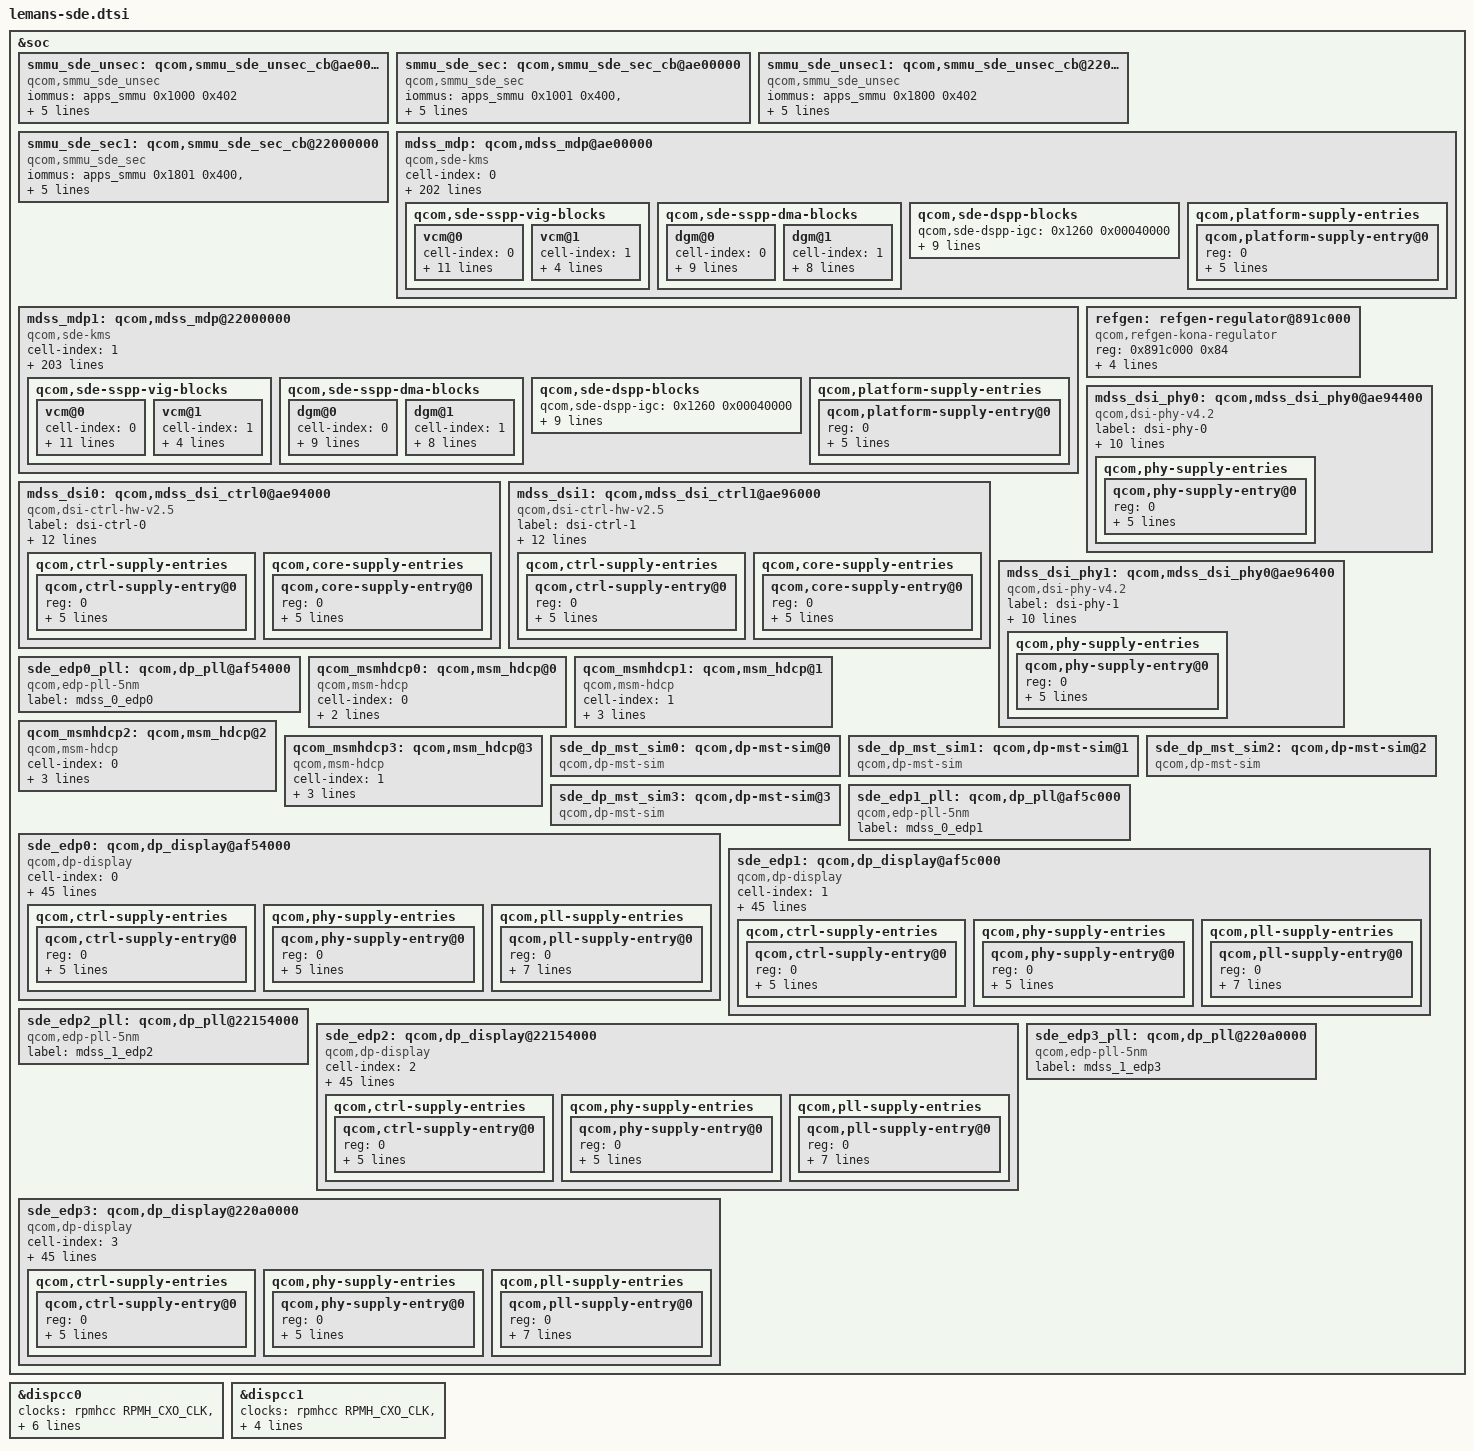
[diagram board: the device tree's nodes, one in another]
#include <dt-bindings/interrupt-controller/irq.h>
#include <dt-bindings/interconnect/qcom,lemans.h>
#include <dt-bindings/regulator/qcom,rpmh-regulator-levels.h>
#include <dt-bindings/clock/qcom,rpmh.h>
#include <dt-bindings/clock/qcom,gcc-lemans.h>
#include <dt-bindings/clock/qcom,dispcc-lemans.h>

&soc {
	smmu_sde_unsec: qcom,smmu_sde_unsec_cb@ae00000 {
		compatible = "qcom,smmu_sde_unsec";
		iommus = <&apps_smmu 0x1000 0x402>;
		qcom,iommu-dma-addr-pool = <0x00020000 0xfffe0000>;
		qcom,iommu-faults = "non-fatal";
		qcom,iommu-earlymap;
		dma-coherent-hint-cached;
	};

	smmu_sde_sec: qcom,smmu_sde_sec_cb@ae00000 {
		compatible = "qcom,smmu_sde_sec";
		iommus = <&apps_smmu 0x1001 0x400>,
			<&apps_smmu 0x1401 0x400>;
		qcom,iommu-dma-addr-pool = <0x00020000 0xfffe0000>;
		qcom,iommu-faults = "non-fatal";
		qcom,iommu-vmid = <0xa>;
	};

	smmu_sde_unsec1: qcom,smmu_sde_unsec_cb@22000000 {
		compatible = "qcom,smmu_sde_unsec";
		iommus = <&apps_smmu 0x1800 0x402>;
		qcom,iommu-dma-addr-pool = <0x00020000 0xfffe0000>;
		qcom,iommu-faults = "non-fatal";
		qcom,iommu-earlymap;
		dma-coherent-hint-cached;
	};

	smmu_sde_sec1: qcom,smmu_sde_sec_cb@22000000 {
		compatible = "qcom,smmu_sde_sec";
		iommus = <&apps_smmu 0x1801 0x400>,
			<&apps_smmu 0x1c01 0x400>;
		qcom,iommu-dma-addr-pool = <0x00020000 0xfffe0000>;
		qcom,iommu-faults = "non-fatal";
		qcom,iommu-vmid = <0xa>;
	};

	mdss_mdp: qcom,mdss_mdp@ae00000 {
		compatible = "qcom,sde-kms";

		cell-index = <0>;

		reg = <0x0ae00000 0x84000>,
				<0x0aeb0000 0x2008>,
				<0x0aeac000 0x800>;
		reg-names = "mdp_phys",
				"vbif_phys",
				"regdma_phys";

		clocks = <&gcc GCC_DISP_HF_AXI_CLK>,
				<&dispcc0 DISP_CC_MDSS_AHB_CLK>,
				<&dispcc0 DISP_CC_MDSS_MDP_CLK>,
				<&dispcc0 DISP_CC_MDSS_VSYNC_CLK>,
				<&dispcc0 DISP_CC_MDSS_MDP_LUT_CLK>;
		clock-names = "gcc_bus", "iface_clk",
				"core_clk", "vsync_clk", "lut_clk";
		clock-rate = <0 0 300000000 19200000 300000000>;
		clock-max-rate = <0 0 460000000 19200000 460000000>;

		sde-vdd-supply = <&disp0_cc_mdss_core_gdsc>;
		mmcx-supply = <&VDD_MMCX_LEVEL>;

		/* interrupt config */
		interrupts = <0 92 IRQ_TYPE_LEVEL_HIGH>;
		interrupt-controller;
		#interrupt-cells = <1>;

		#address-cells = <1>;
		#size-cells = <0>;

		#power-domain-cells = <0>;

		/* hw blocks */
		qcom,sde-off = <0x1000>;
		qcom,sde-len = <0x494>;

		qcom,sde-ctl-off = <0x16000 0x17000 0x18000
				0x19000 0x1a000 0x1b000>;
		qcom,sde-ctl-size = <0x204>;
		qcom,sde-ctl-display-pref = "primary", "none", "none",
				"none", "none", "none";

		qcom,sde-mixer-off = <0x45000 0x46000 0x47000
				0x48000 0x49000 0x4a000
				0x0f0f 0x0f0f>;
		qcom,sde-mixer-size = <0x400>;
		qcom,sde-mixer-display-pref = "primary", "none", "none",
				"none", "none", "none", "none", "none";

		qcom,sde-mixer-dcwb-pref = "none", "none", "none", "none",
				"none", "none", "dcwb", "dcwb";

		qcom,sde-dspp-top-off = <0x1300>;
		qcom,sde-dspp-top-size = <0x80>;
		qcom,sde-dspp-off = <0x55000 0x57000 0x59000 0x5b000>;
		qcom,sde-dspp-size = <0x1800>;

		qcom,sde-dspp-rc-version = <0x00010000>;
		qcom,sde-dspp-rc-off = <0x15800 0x14c00>;
		qcom,sde-dspp-rc-size = <0x100>;
		qcom,sde-dspp-rc-mem-size = <2720>;

		qcom,sde-dest-scaler-top-off = <0x00061000>;
		qcom,sde-dest-scaler-top-size = <0x1c>;
		qcom,sde-dest-scaler-off = <0x800 0x1000>;
		qcom,sde-dest-scaler-size = <0x800>;

		qcom,sde-wb-off = <0x66000>;
		qcom,sde-wb-size = <0x2c8>;
		qcom,sde-wb-xin-id = <6>;
		qcom,sde-wb-id = <2>;
		qcom,sde-wb-clk-ctrl = <0x2bc 16>;
		qcom,sde-wb-clk-status = <0x3bc 20>;

		qcom,sde-intf-off = <0x35000 0x36000 0x37000 0x38000
				0x39000 0x3a000 0x3b000 0x3c000 0x3d000>;
		qcom,sde-intf-size = <0x2c4>;
		qcom,sde-intf-type = "dp", "dsi", "dsi", "dp",
				"dp", "dp", "dp", "dp", "dp";
		qcom,sde-intf-tear-irq-off = <0 0x36800 0x37800 0
				0 0 0 0 0>;

		qcom,sde-pp-off = <0x6a000 0x6b000 0x6c000 0x6d000
				0x6e000 0x6f000 0x66800 0x66c00>;
		qcom,sde-pp-slave = <0x0 0x0 0x0 0x0 0x0 0x0 0x0 0x0>;
		qcom,sde-pp-size = <0xd4>;
		qcom,sde-pp-merge-3d-id = <0x0 0x0 0x1 0x1 0x2 0x2 0x3 0x3>;

		qcom,sde-merge-3d-off = <0x4f000 0x50000 0x51000 0x66f00>;
		qcom,sde-merge-3d-size = <0x10>;
		qcom,sde-pp-cwb = <0x0 0x0 0x0 0x0 0x0 0x0 0x1 0x1>;

		qcom,sde-cdm-off = <0x7a200>;
		qcom,sde-cdm-size = <0x224>;

		qcom,sde-dsc-off = <0x81000 0x81000 0x82000 0x82000>;
		qcom,sde-dsc-size = <0x10>;
		qcom,sde-dsc-pair-mask = <2 1 4 3>;
		qcom,sde-dsc-hw-rev = "dsc_1_2";
		qcom,sde-dsc-enc = <0x100 0x200 0x100 0x200>;
		qcom,sde-dsc-enc-size = <0x100>;
		qcom,sde-dsc-ctl = <0xF00 0xF80 0xF00 0xF80>;
		qcom,sde-dsc-ctl-size = <0x10>;
		qcom,sde-dsc-native422-supp = <0 0 1 1>;
		qcom,sde-dsc-linewidth = <2560>;

		qcom,sde-roi-misr-off = <0x72000 0x73000 0x74000
				0x75000 0x76000 0x77000>;
		qcom,sde-roi-misr-size = <0x180>;
		qcom,sde-roi-misr-bypass-off = <0xA00>;
		qcom,sde-roi-misr-bypass-size = <0xC0>;

		qcom,sde-dither-off = <0xe0 0xe0 0xe0
				0xe0 0xe0 0xe0 0xe0 0xe0>;
		qcom,sde-cwb-dither = <0x0 0x0 0x0 0x0 0x0 0x0 0x1 0x1>;
		qcom,sde-dither-version = <0x00020000>;
		qcom,sde-dither-size = <0x20>;

		qcom,sde-sspp-type = "vig", "vig", "vig", "vig",
				"dma", "dma", "dma", "dma";

		qcom,sde-sspp-off = <0x5000 0x7000 0x9000 0xb000
				0x25000 0x27000 0x29000 0x2b000>;
		qcom,sde-sspp-src-size = <0x328>;

		qcom,sde-sspp-xin-id = <0 4 8 12
				1 5 9 13>;
		qcom,sde-sspp-excl-rect = <1 1 1 1
				1 1 1 1>;
		qcom,sde-sspp-smart-dma-priority = <5 6 7 8 1 2 3 4>;
		qcom,sde-smart-dma-rev = "smart_dma_v2p5";

		qcom,sde-mixer-pair-mask = <2 1 4 3 6 5 8 7>;

		qcom,sde-mixer-blend-op-off = <0x20 0x38 0x50 0x68 0x80 0x98
				0xb0 0xc8 0xe0 0xf8 0x110>;

		qcom,sde-max-per-pipe-bw-kbps = <4500000 4500000
				4500000 4500000
				4500000 4500000
				4500000 4500000>;

		qcom,sde-max-per-pipe-bw-high-kbps = <5200000 5200000
				5200000 5200000
				5200000 5200000
				5200000 5200000>;

		/* offsets are relative to "mdp_phys + qcom,sde-off */
		qcom,sde-sspp-clk-ctrl =
				<0x2ac 0>, <0x2b4 0>,
				<0x2bc 0>, <0x2c4 0>,
				<0x2ac 8>, <0x2b4 8>,
				<0x2bc 8>, <0x2c4 8>;
		qcom,sde-sspp-clk-status =
				<0x2b0 0>, <0x2b8 0>,
				<0x2c0 0>, <0x2c8 0>,
				<0x2b0 12>, <0x2b8 12>,
				<0x2c8 12>, <0x2c8 14>;
		qcom,sde-sspp-csc-off = <0x1a00>;
		qcom,sde-csc-type = "csc-10bit";
		qcom,sde-qseed-sw-lib-rev = "qseedv3lite";
		qcom,sde-qseed-scalar-version = <0x3000>;
		qcom,sde-sspp-qseed-off = <0xa00>;
		qcom,sde-mixer-linewidth = <2560>;
		qcom,sde-sspp-linewidth = <5120>;
		qcom,sde-wb-linewidth = <4096>;
		qcom,sde-wb-linewidth-linear = <5120>;
		qcom,sde-mixer-blendstages = <0xb>;
		qcom,sde-highest-bank-bit = <0x8 0x0>,
				<0x7 0x2>;
		qcom,sde-ubwc-version = <0x40000000>;
		qcom,sde-ubwc-swizzle = <0x4>;
		qcom,sde-ubwc-bw-calc-version = <0x1>;
		qcom,sde-ubwc-static = <0x1>;
		qcom,sde-macrotile-mode = <0x1>;
		qcom,sde-smart-panel-align-mode = <0xc>;
		qcom,sde-panic-per-pipe;
		qcom,sde-has-cdp;
		qcom,sde-has-src-split;
		qcom,sde-pipe-order-version = <0x1>;
		qcom,sde-has-dim-layer;
		qcom,sde-has-idle-pc;

		qcom,sde-dspp-ltm-version = <0x00010001>;
		/* offsets are based off dspp 0 and dspp 1 */
		qcom,sde-dspp-ltm-off = <0x15300 0x14300>;

		qcom,sde-max-dest-scaler-input-linewidth = <2048>;
		qcom,sde-max-dest-scaler-output-linewidth = <2560>;
		qcom,sde-max-bw-low-kbps = <13600000>;
		qcom,sde-max-bw-high-kbps = <18200000>;
		qcom,sde-min-core-ib-kbps = <2500000>;
		qcom,sde-min-llcc-ib-kbps = <0>;
		qcom,sde-min-dram-ib-kbps = <800000>;
		qcom,sde-dram-channels = <2>;
		qcom,sde-num-nrt-paths = <0>;

		qcom,sde-dspp-demura-off = <0x15600 0x14800>;
		qcom,sde-dspp-demura-size = <0x200>;
		qcom,sde-dspp-demura-version = <0x00010000>;

		qcom,sde-lm-noise-off = <0x320>;
		qcom,sde-lm-noise-version = <0x00010000>;

		qcom,sde-uidle-off = <0x80000>;
		qcom,sde-uidle-size = <0x70>;

		qcom,sde-vbif-off = <0>;
		qcom,sde-vbif-size = <0x1040>;
		qcom,sde-vbif-id = <0>;
		qcom,sde-vbif-memtype-0 = <3 3 3 3 3 3 3 3>;
		qcom,sde-vbif-memtype-1 = <3 3 3 3 3 3>;

		qcom,sde-vbif-default-ot-wr-limit = <16>;
		qcom,sde-vbif-dynamic-ot-wr-limit = <62208000 2 124416000 6 497664000 16>;

		qcom,sde-vbif-qos-rt-remap = <3 3 4 4 5 5 6 6 3 3 4 4 5 5 6 6>;
		qcom,sde-vbif-qos-nrt-remap = <3 3 3 3 3 3 3 3 3 3 3 3 3 3 3 3>;
		qcom,sde-vbif-qos-cwb-remap = <3 3 4 4 5 5 6 6 3 3 4 4 5 5 6 6>;
		qcom,sde-vbif-qos-lutdma-remap = <3 3 3 3 4 4 4 6 3 3 3 3 4 4 4 6>;

		qcom,sde-qos-refresh-rates = <120 240>;
		qcom,sde-danger-lut = <0x3ffff 0x3ffff 0x0 0x0 0x0 0x3fffff 0x3fffff>,
				<0x3ffffff 0x3ffffff 0x0 0x0 0x0 0x3ffffff 0x3fffff>;

		qcom,sde-safe-lut = <0xFE00 0xFE00 0xFFFF 0x01 0x03FF 0xF800 0xF800>,
				<0xE000 0xE000 0xFFFF 0x01 0x03FF 0xE000 0xF800>;

		qcom,sde-creq-lut =
				<0x00112234 0x45566777 0x00112236 0x67777777
				    0x00112234 0x45566777 0x00112236 0x67777777
				    0x0        0x0         0x0        0x0
				    0x77776666 0x66666540 0x77776666 0x66666540
				    0x77776541 0x00000000 0x77776541 0x00000000
				    0x00123445 0x56677777 0x00123667 0x77777777
				    0x00123445 0x56677777 0x00123667 0x77777777>,
				<0x02344455 0x56667777 0x02366677 0x77777777
				    0x02344455 0x56667777 0x02366677 0x77777777
				    0x0        0x0        0x0        0x0
				    0x77776666 0x66666540 0x77776666 0x66666540
				    0x77776541 0x00000000 0x77776541 0x00000000
				    0x02344455 0x56667777 0x02366677 0x77777777
				    0x00123445 0x56677777 0x00123667 0x77777777>;

		qcom,sde-cdp-setting = <1 1>, <1 0>;

		qcom,sde-qos-cpu-mask = <0x3>;
		qcom,sde-qos-cpu-mask-performance = <0xf>;
		qcom,sde-qos-cpu-dma-latency = <300>;
		qcom,sde-qos-cpu-irq-latency = <300>;

		/* offsets are relative to "mdp_phys + qcom,sde-off */
		qcom,sde-reg-dma-off = <0 0x400>;
		qcom,sde-reg-dma-id = <0 1>;
		qcom,sde-reg-dma-version = <0x00020000>;
		qcom,sde-reg-dma-trigger-off = <0x119c>;
		qcom,sde-reg-dma-xin-id = <7>;
		qcom,sde-reg-dma-clk-ctrl = <0x2bc 20>;

		qcom,sde-secure-sid-mask = <0x4000821>;

		qcom,sde-reg-bus,vectors-KBps = <0 0>,
				<0 74000>,
				<0 148000>,
				<0 265000>;

		/* data and reg bus scale settings */
		interconnects = <&mmss_noc MASTER_MDP0 &gem_noc SLAVE_LLCC>,
				<&mmss_noc MASTER_MDP1 &gem_noc SLAVE_LLCC>,
				<&mc_virt MASTER_LLCC &mc_virt SLAVE_EBI1>,
				<&gem_noc MASTER_APPSS_PROC &config_noc SLAVE_DISPLAY_CFG>;
		interconnect-names = "qcom,sde-data-bus0", "qcom,sde-data-bus1",
				"qcom,sde-ebi-bus", "qcom,sde-reg-bus";

		qcom,sde-ib-bw-vote = <2500000 0 800000>;

		qcom,sde-sspp-vig-blocks {
			vcm@0 {
				cell-index = <0>;
				qcom,sde-vig-top-off = <0xa00>;
				qcom,sde-vig-csc-off = <0x1a00>;
				qcom,sde-vig-qseed-off = <0xa00>;
				qcom,sde-vig-qseed-size = <0xe0>;
				qcom,sde-vig-gamut = <0x1d00 0x00060001>;
				qcom,sde-vig-igc = <0x1d00 0x00060000>;
				qcom,sde-vig-inverse-pma;
				qcom,sde-fp16-igc = <0x200 0x00010000>;
				qcom,sde-fp16-unmult = <0x200 0x00010000>;
				qcom,sde-fp16-gc = <0x200 0x00010000>;
				qcom,sde-fp16-csc = <0x200 0x00010000>;
			};

			vcm@1 {
				cell-index = <1>;
				qcom,sde-fp16-igc = <0x280 0x00010000>;
				qcom,sde-fp16-unmult = <0x280 0x00010000>;
				qcom,sde-fp16-gc = <0x280 0x00010000>;
				qcom,sde-fp16-csc = <0x280 0x00010000>;
			};
		};

		qcom,sde-sspp-dma-blocks {
			dgm@0 {
				cell-index = <0>;
				qcom,sde-dma-top-off = <0x800>;
				qcom,sde-dma-igc = <0xa00 0x00050000>;
				qcom,sde-dma-gc = <0xc00 0x00050000>;
				qcom,sde-dma-inverse-pma;
				qcom,sde-dma-csc-off = <0x800>;
				qcom,sde-fp16-igc = <0x200 0x00010000>;
				qcom,sde-fp16-unmult = <0x200 0x00010000>;
				qcom,sde-fp16-gc = <0x200 0x00010000>;
				qcom,sde-fp16-csc = <0x200 0x00010000>;
			};

			dgm@1 {
				cell-index = <1>;
				qcom,sde-dma-igc = <0x1a00 0x00050000>;
				qcom,sde-dma-gc = <0xc00 0x00050000>;
				qcom,sde-dma-inverse-pma;
				qcom,sde-dma-csc-off = <0x1800>;
				qcom,sde-fp16-igc = <0x200 0x00010000>;
				qcom,sde-fp16-unmult = <0x200 0x00010000>;
				qcom,sde-fp16-gc = <0x200 0x00010000>;
				qcom,sde-fp16-csc = <0x200 0x00010000>;
			};
		};

		qcom,sde-dspp-blocks {
			qcom,sde-dspp-igc = <0x1260 0x00040000>;
			qcom,sde-dspp-hsic = <0x800 0x00010007>;
			qcom,sde-dspp-memcolor = <0x880 0x00010007>;
			qcom,sde-dspp-hist = <0x800 0x00010007>;
			qcom,sde-dspp-sixzone= <0x900 0x00010007>;
			qcom,sde-dspp-vlut = <0xa00 0x00010008>;
			qcom,sde-dspp-gamut = <0x1000 0x00040003>;
			qcom,sde-dspp-pcc = <0x1700 0x00040000>;
			qcom,sde-dspp-gc = <0x17c0 0x00010008>;
			qcom,sde-dspp-dither = <0x82c 0x00010007>;
		};

		qcom,platform-supply-entries {
			#address-cells = <1>;
			#size-cells = <0>;

			qcom,platform-supply-entry@0 {
				reg = <0>;
				qcom,supply-name = "mmcx";
				qcom,supply-min-voltage = <0>;
				qcom,supply-max-voltage = <0>;
				qcom,supply-enable-load = <0>;
				qcom,supply-disable-load = <0>;
			};
		};
	};

	mdss_mdp1: qcom,mdss_mdp@22000000 {
		compatible = "qcom,sde-kms";

		cell-index = <1>;

		reg = <0x22000000 0x84000>,
				<0x220b0000 0x2008>,
				<0x220ac000 0x800>;
		reg-names = "mdp_phys",
				"vbif_phys",
				"regdma_phys";

		clocks = <&gcc GCC_DISP1_HF_AXI_CLK>,
				<&dispcc1 DISP_CC_MDSS_AHB_CLK>,
				<&dispcc1 DISP_CC_MDSS_MDP_CLK>,
				<&dispcc1 DISP_CC_MDSS_VSYNC_CLK>,
				<&dispcc1 DISP_CC_MDSS_MDP_LUT_CLK>;
		clock-names = "gcc_bus", "iface_clk",
				"core_clk", "vsync_clk", "lut_clk";
		clock-rate = <0 0 300000000 19200000 300000000>;
		clock-max-rate = <0 0 460000000 19200000 460000000>;

		sde-vdd-supply = <&disp1_cc_mdss_core_gdsc>;
		mmcx-supply = <&VDD_MMCX_LEVEL>;

		/* interrupt config */
		interrupts = <0 865 IRQ_TYPE_LEVEL_HIGH>;
		interrupt-controller;
		#interrupt-cells = <1>;

		#address-cells = <1>;
		#size-cells = <0>;

		#power-domain-cells = <0>;

		/* hw blocks */
		qcom,sde-off = <0x1000>;
		qcom,sde-len = <0x494>;

		qcom,sde-ctl-off = <0x16000 0x17000 0x18000
				0x19000 0x1a000 0x1b000>;
		qcom,sde-ctl-size = <0x204>;
		qcom,sde-ctl-display-pref = "primary", "none", "none",
				"none", "none", "none";

		qcom,sde-mixer-off = <0x45000 0x46000 0x47000
				0x48000 0x49000 0x4a000
				0x0f0f 0x0f0f>;
		qcom,sde-mixer-size = <0x400>;
		qcom,sde-mixer-display-pref = "primary", "none", "none",
				"none", "none", "none", "none", "none";

		qcom,sde-mixer-dcwb-pref = "none", "none", "none", "none",
				"none", "none", "dcwb", "dcwb";

		qcom,sde-dspp-top-off = <0x1300>;
		qcom,sde-dspp-top-size = <0x80>;
		qcom,sde-dspp-off = <0x55000 0x57000 0x59000 0x5b000>;
		qcom,sde-dspp-size = <0x1800>;

		qcom,sde-dspp-rc-version = <0x00010000>;
		qcom,sde-dspp-rc-off = <0x15800 0x14c00>;
		qcom,sde-dspp-rc-size = <0x100>;
		qcom,sde-dspp-rc-mem-size = <2720>;

		qcom,sde-dest-scaler-top-off = <0x00061000>;
		qcom,sde-dest-scaler-top-size = <0x1c>;
		qcom,sde-dest-scaler-off = <0x800 0x1000>;
		qcom,sde-dest-scaler-size = <0x800>;

		qcom,sde-wb-off = <0x66000>;
		qcom,sde-wb-size = <0x2c8>;
		qcom,sde-wb-xin-id = <6>;
		qcom,sde-wb-id = <2>;
		qcom,sde-wb-clk-ctrl = <0x2bc 16>;
		qcom,sde-wb-clk-status = <0x3bc 20>;

		qcom,sde-intf-off = <0x35000 0x36000 0x37000 0x38000
				0x39000 0x3a000 0x3b000 0x3c000 0x3d000>;
		qcom,sde-intf-size = <0x2c4>;
		qcom,sde-intf-type = "dp", "dsi", "dsi", "dp",
				"dp", "dp", "dp", "dp", "dp";
		qcom,sde-intf-tear-irq-off = <0 0x36800 0x37800 0
				0 0 0 0 0>;

		qcom,sde-pp-off = <0x6a000 0x6b000 0x6c000 0x6d000
				0x6e000 0x6f000 0x66800 0x66c00>;
		qcom,sde-pp-slave = <0x0 0x0 0x0 0x0 0x0 0x0 0x0 0x0>;
		qcom,sde-pp-size = <0xd4>;
		qcom,sde-pp-merge-3d-id = <0x0 0x0 0x1 0x1 0x2 0x2 0x3 0x3>;

		qcom,sde-merge-3d-off = <0x4f000 0x50000 0x51000 0x66f00>;
		qcom,sde-merge-3d-size = <0x10>;
		qcom,sde-pp-cwb = <0x0 0x0 0x0 0x0 0x0 0x0 0x1 0x1>;

		qcom,sde-cdm-off = <0x7a200>;
		qcom,sde-cdm-size = <0x224>;

		qcom,sde-dsc-off = <0x81000 0x81000 0x82000 0x82000>;
		qcom,sde-dsc-size = <0x10>;
		qcom,sde-dsc-pair-mask = <2 1 4 3>;
		qcom,sde-dsc-hw-rev = "dsc_1_2";
		qcom,sde-dsc-enc = <0x100 0x200 0x100 0x200>;
		qcom,sde-dsc-enc-size = <0x100>;
		qcom,sde-dsc-ctl = <0xF00 0xF80 0xF00 0xF80>;
		qcom,sde-dsc-ctl-size = <0x10>;
		qcom,sde-dsc-native422-supp = <0 0 1 1>;
		qcom,sde-dsc-linewidth = <2560>;

		qcom,sde-roi-misr-off = <0x72000 0x73000 0x74000
				0x75000 0x76000 0x77000>;
		qcom,sde-roi-misr-size = <0x180>;
		qcom,sde-roi-misr-bypass-off = <0xA00>;
		qcom,sde-roi-misr-bypass-size = <0xC0>;

		qcom,sde-dither-off = <0xe0 0xe0 0xe0
				0xe0 0xe0 0xe0 0xe0 0xe0>;
		qcom,sde-cwb-dither = <0x0 0x0 0x0 0x0 0x0 0x0 0x1 0x1>;
		qcom,sde-dither-version = <0x00020000>;
		qcom,sde-dither-size = <0x20>;

		qcom,sde-sspp-type = "vig", "vig", "vig", "vig",
				"dma", "dma", "dma", "dma";

		qcom,sde-sspp-off = <0x5000 0x7000 0x9000 0xb000
				0x25000 0x27000 0x29000 0x2b000>;
		qcom,sde-sspp-src-size = <0x328>;

		qcom,sde-sspp-xin-id = <0 4 8 12
				1 5 9 13>;
		qcom,sde-sspp-excl-rect = <1 1 1 1
				1 1 1 1>;
		qcom,sde-sspp-smart-dma-priority = <5 6 7 8 1 2 3 4>;
		qcom,sde-smart-dma-rev = "smart_dma_v2p5";

		qcom,sde-mixer-pair-mask = <2 1 4 3 6 5 8 7>;

		qcom,sde-mixer-blend-op-off = <0x20 0x38 0x50 0x68 0x80 0x98
				0xb0 0xc8 0xe0 0xf8 0x110>;

		qcom,sde-max-per-pipe-bw-kbps = <4500000 4500000
				4500000 4500000
				4500000 4500000
				4500000 4500000>;

		qcom,sde-max-per-pipe-bw-high-kbps = <5200000 5200000
				5200000 5200000
				5200000 5200000
				5200000 5200000>;

		/* offsets are relative to "mdp_phys + qcom,sde-off */
		qcom,sde-sspp-clk-ctrl =
				<0x2ac 0>, <0x2b4 0>,
				<0x2bc 0>, <0x2c4 0>,
				<0x2ac 8>, <0x2b4 8>,
				<0x2bc 8>, <0x2c4 8>;
		qcom,sde-sspp-clk-status =
				<0x2b0 0>, <0x2b8 0>,
				<0x2c0 0>, <0x2c8 0>,
				<0x2b0 12>, <0x2b8 12>,
				<0x2c8 12>, <0x2c8 14>;
		qcom,sde-sspp-csc-off = <0x1a00>;
		qcom,sde-csc-type = "csc-10bit";
		qcom,sde-qseed-sw-lib-rev = "qseedv3lite";
		qcom,sde-qseed-scalar-version = <0x3000>;
		qcom,sde-sspp-qseed-off = <0xa00>;
		qcom,sde-mixer-linewidth = <2560>;
		qcom,sde-sspp-linewidth = <5120>;
		qcom,sde-wb-linewidth = <4096>;
		qcom,sde-wb-linewidth-linear = <5120>;
		qcom,sde-mixer-blendstages = <0xb>;
		qcom,sde-highest-bank-bit = <0x8 0x0>,
				<0x7 0x2>;
		qcom,sde-ubwc-version = <0x40000000>;
		qcom,sde-ubwc-swizzle = <0x4>;
		qcom,sde-ubwc-bw-calc-version = <0x1>;
		qcom,sde-ubwc-static = <0x1>;
		qcom,sde-macrotile-mode = <0x1>;
		qcom,sde-smart-panel-align-mode = <0xc>;
		qcom,sde-panic-per-pipe;
		qcom,sde-has-cdp;
		qcom,sde-has-src-split;
		qcom,sde-pipe-order-version = <0x1>;
		qcom,sde-has-dim-layer;
		qcom,sde-has-idle-pc;

		qcom,sde-dspp-ltm-version = <0x00010001>;
		/* offsets are based off dspp 0 and dspp 1 */
		qcom,sde-dspp-ltm-off = <0x15300 0x14300>;

		qcom,sde-max-dest-scaler-input-linewidth = <2048>;
		qcom,sde-max-dest-scaler-output-linewidth = <2560>;
		qcom,sde-max-bw-low-kbps = <13600000>;
		qcom,sde-max-bw-high-kbps = <18200000>;
		qcom,sde-min-core-ib-kbps = <2500000>;
		qcom,sde-min-llcc-ib-kbps = <0>;
		qcom,sde-min-dram-ib-kbps = <800000>;
		qcom,sde-dram-channels = <2>;
		qcom,sde-num-nrt-paths = <0>;

		qcom,sde-dspp-demura-off = <0x15600 0x14800>;
		qcom,sde-dspp-demura-size = <0x200>;
		qcom,sde-dspp-demura-version = <0x00010000>;

		qcom,sde-lm-noise-off = <0x320>;
		qcom,sde-lm-noise-version = <0x00010000>;

		qcom,sde-uidle-off = <0x80000>;
		qcom,sde-uidle-size = <0x70>;

		qcom,sde-vbif-off = <0>;
		qcom,sde-vbif-size = <0x1040>;
		qcom,sde-vbif-id = <0>;
		qcom,sde-vbif-memtype-0 = <3 3 3 3 3 3 3 3>;
		qcom,sde-vbif-memtype-1 = <3 3 3 3 3 3>;

		qcom,sde-vbif-default-ot-wr-limit = <16>;
		qcom,sde-vbif-dynamic-ot-wr-limit = <62208000 2 124416000 6 497664000 16>;

		qcom,sde-vbif-qos-rt-remap = <3 3 4 4 5 5 6 6 3 3 4 4 5 5 6 6>;
		qcom,sde-vbif-qos-nrt-remap = <3 3 3 3 3 3 3 3 3 3 3 3 3 3 3 3>;
		qcom,sde-vbif-qos-cwb-remap = <3 3 4 4 5 5 6 6 3 3 4 4 5 5 6 6>;
		qcom,sde-vbif-qos-lutdma-remap = <3 3 3 3 4 4 4 6 3 3 3 3 4 4 4 6>;

		qcom,sde-qos-refresh-rates = <120 240>;
		qcom,sde-danger-lut = <0x3ffff 0x3ffff 0x0 0x0 0x0 0x3fffff 0x3fffff>,
				<0x3ffffff 0x3ffffff 0x0 0x0 0x0 0x3ffffff 0x3fffff>;

		qcom,sde-safe-lut = <0xFE00 0xFE00 0xFFFF 0x01 0x03FF 0xF800 0xF800>,
				<0xE000 0xE000 0xFFFF 0x01 0x03FF 0xE000 0xF800>;

		qcom,sde-creq-lut =
				<0x00112234 0x45566777 0x00112236 0x67777777
				    0x00112234 0x45566777 0x00112236 0x67777777
				    0x0        0x0         0x0        0x0
				    0x77776666 0x66666540 0x77776666 0x66666540
				    0x77776541 0x00000000 0x77776541 0x00000000
				    0x00123445 0x56677777 0x00123667 0x77777777
				    0x00123445 0x56677777 0x00123667 0x77777777>,
				<0x02344455 0x56667777 0x02366677 0x77777777
				    0x02344455 0x56667777 0x02366677 0x77777777
				    0x0        0x0        0x0        0x0
				    0x77776666 0x66666540 0x77776666 0x66666540
				    0x77776541 0x00000000 0x77776541 0x00000000
				    0x02344455 0x56667777 0x02366677 0x77777777
				    0x00123445 0x56677777 0x00123667 0x77777777>;

		qcom,sde-cdp-setting = <1 1>, <1 0>;

		qcom,sde-qos-cpu-mask = <0x3>;
		qcom,sde-qos-cpu-mask-performance = <0xf>;
		qcom,sde-qos-cpu-dma-latency = <300>;
		qcom,sde-qos-cpu-irq-latency = <300>;

		/* offsets are relative to "mdp_phys + qcom,sde-off */
		qcom,sde-reg-dma-off = <0 0x400>;
		qcom,sde-reg-dma-id = <0 1>;
		qcom,sde-reg-dma-version = <0x00020000>;
		qcom,sde-reg-dma-trigger-off = <0x119c>;
		qcom,sde-reg-dma-xin-id = <7>;
		qcom,sde-reg-dma-clk-ctrl = <0x2bc 20>;

		qcom,sde-secure-sid-mask = <0x4000821>;

		qcom,sde-reg-bus,vectors-KBps = <0 0>,
				<0 74000>,
				<0 148000>,
				<0 265000>;

		/* data and reg bus scale settings */
		interconnects = <&mmss_noc MASTER_MDP_CORE1_0 &gem_noc SLAVE_LLCC>,
				<&mmss_noc MASTER_MDP_CORE1_1 &gem_noc SLAVE_LLCC>,
				<&mc_virt MASTER_LLCC &mc_virt SLAVE_EBI1>,
				<&gem_noc MASTER_APPSS_PROC &config_noc SLAVE_DISPLAY1_CFG>;
		interconnect-names = "qcom,sde-data-bus0", "qcom,sde-data-bus1",
				"qcom,sde-ebi-bus", "qcom,sde-reg-bus";

		qcom,sde-ib-bw-vote = <2500000 0 800000>;

		qcom,sde-sspp-vig-blocks {
			vcm@0 {
				cell-index = <0>;
				qcom,sde-vig-top-off = <0xa00>;
				qcom,sde-vig-csc-off = <0x1a00>;
				qcom,sde-vig-qseed-off = <0xa00>;
				qcom,sde-vig-qseed-size = <0xe0>;
				qcom,sde-vig-gamut = <0x1d00 0x00060001>;
				qcom,sde-vig-igc = <0x1d00 0x00060000>;
				qcom,sde-vig-inverse-pma;
				qcom,sde-fp16-igc = <0x200 0x00010000>;
				qcom,sde-fp16-unmult = <0x200 0x00010000>;
				qcom,sde-fp16-gc = <0x200 0x00010000>;
				qcom,sde-fp16-csc = <0x200 0x00010000>;
			};

			vcm@1 {
				cell-index = <1>;
				qcom,sde-fp16-igc = <0x280 0x00010000>;
				qcom,sde-fp16-unmult = <0x280 0x00010000>;
				qcom,sde-fp16-gc = <0x280 0x00010000>;
				qcom,sde-fp16-csc = <0x280 0x00010000>;
			};
		};

		qcom,sde-sspp-dma-blocks {
			dgm@0 {
				cell-index = <0>;
				qcom,sde-dma-top-off = <0x800>;
				qcom,sde-dma-igc = <0xa00 0x00050000>;
				qcom,sde-dma-gc = <0xc00 0x00050000>;
				qcom,sde-dma-inverse-pma;
				qcom,sde-dma-csc-off = <0x800>;
				qcom,sde-fp16-igc = <0x200 0x00010000>;
				qcom,sde-fp16-unmult = <0x200 0x00010000>;
				qcom,sde-fp16-gc = <0x200 0x00010000>;
				qcom,sde-fp16-csc = <0x200 0x00010000>;
			};

			dgm@1 {
				cell-index = <1>;
				qcom,sde-dma-igc = <0x1a00 0x00050000>;
				qcom,sde-dma-gc = <0xc00 0x00050000>;
				qcom,sde-dma-inverse-pma;
				qcom,sde-dma-csc-off = <0x1800>;
				qcom,sde-fp16-igc = <0x200 0x00010000>;
				qcom,sde-fp16-unmult = <0x200 0x00010000>;
				qcom,sde-fp16-gc = <0x200 0x00010000>;
				qcom,sde-fp16-csc = <0x200 0x00010000>;
			};
		};

		qcom,sde-dspp-blocks {
			qcom,sde-dspp-igc = <0x1260 0x00040000>;
			qcom,sde-dspp-hsic = <0x800 0x00010007>;
			qcom,sde-dspp-memcolor = <0x880 0x00010007>;
			qcom,sde-dspp-hist = <0x800 0x00010007>;
			qcom,sde-dspp-sixzone= <0x900 0x00010007>;
			qcom,sde-dspp-vlut = <0xa00 0x00010008>;
			qcom,sde-dspp-gamut = <0x1000 0x00040003>;
			qcom,sde-dspp-pcc = <0x1700 0x00040000>;
			qcom,sde-dspp-gc = <0x17c0 0x00010008>;
			qcom,sde-dspp-dither = <0x82c 0x00010007>;
		};

		qcom,platform-supply-entries {
			#address-cells = <1>;
			#size-cells = <0>;

			qcom,platform-supply-entry@0 {
				reg = <0>;
				qcom,supply-name = "mmcx";
				qcom,supply-min-voltage = <0>;
				qcom,supply-max-voltage = <0>;
				qcom,supply-enable-load = <0>;
				qcom,supply-disable-load = <0>;
			};
		};
	};

	refgen: refgen-regulator@891c000 {
		compatible = "qcom,refgen-kona-regulator";
		reg = <0x891c000 0x84>;
		regulator-name = "refgen";
		proxy-supply = <&refgen>;
		qcom,proxy-consumer-enable;
		regulator-enable-ramp-delay = <5>;
	};

	mdss_dsi0: qcom,mdss_dsi_ctrl0@ae94000 {
		compatible = "qcom,dsi-ctrl-hw-v2.5";
		label = "dsi-ctrl-0";
		cell-index = <0>;
		reg = <0xae94000 0x400>,
				<0xaf0f000 0x4>,
				<0xae36000 0x300>;
		reg-names = "dsi_ctrl", "disp_cc_base", "mdp_intf_base";
		interrupt-parent = <&mdss_mdp>;
		interrupts = <4 0>;
		clocks = <&dispcc0 DISP_CC_MDSS_BYTE0_CLK>,
				<&dispcc0 DISP_CC_MDSS_BYTE0_CLK_SRC>,
				<&dispcc0 DISP_CC_MDSS_BYTE0_INTF_CLK>,
				<&dispcc0 DISP_CC_MDSS_PCLK0_CLK>,
				<&dispcc0 DISP_CC_MDSS_PCLK0_CLK_SRC>,
				<&dispcc0 DISP_CC_MDSS_ESC0_CLK>,
				<&rpmhcc RPMH_CXO_CLK>;
		clock-names = "byte_clk", "byte_clk_rcg", "byte_intf_clk",
				"pixel_clk", "pixel_clk_rcg",
				"esc_clk", "xo";

		qcom,ctrl-supply-entries {
			#address-cells = <1>;
			#size-cells = <0>;

			qcom,ctrl-supply-entry@0 {
				reg = <0>;
				qcom,supply-name = "vdda-1p2";
				qcom,supply-min-voltage = <1200000>;
				qcom,supply-max-voltage = <1200000>;
				qcom,supply-enable-load = <30100>;
				qcom,supply-disable-load = <0>;
			};
		};

		qcom,core-supply-entries {
			#address-cells = <1>;
			#size-cells = <0>;
			qcom,core-supply-entry@0 {
				reg = <0>;
				qcom,supply-name = "refgen";
				qcom,supply-min-voltage = <0>;
				qcom,supply-max-voltage = <0>;
				qcom,supply-enable-load = <0>;
				qcom,supply-disable-load = <0>;
			};
		};
	};

	mdss_dsi1: qcom,mdss_dsi_ctrl1@ae96000 {
		compatible = "qcom,dsi-ctrl-hw-v2.5";
		label = "dsi-ctrl-1";
		cell-index = <1>;
		reg = <0xae96000 0x400>,
				<0xaf0f000 0x4>,
				<0xae37000 0x300>;
		reg-names = "dsi_ctrl", "disp_cc_base", "mdp_intf_base";
		interrupt-parent = <&mdss_mdp>;
		interrupts = <5 0>;
		clocks = <&dispcc0 DISP_CC_MDSS_BYTE1_CLK>,
				<&dispcc0 DISP_CC_MDSS_BYTE1_CLK_SRC>,
				<&dispcc0 DISP_CC_MDSS_BYTE1_INTF_CLK>,
				<&dispcc0 DISP_CC_MDSS_PCLK1_CLK>,
				<&dispcc0 DISP_CC_MDSS_PCLK1_CLK_SRC>,
				<&dispcc0 DISP_CC_MDSS_ESC1_CLK>,
				<&rpmhcc RPMH_CXO_CLK>;
		clock-names = "byte_clk", "byte_clk_rcg", "byte_intf_clk",
				"pixel_clk", "pixel_clk_rcg",
				"esc_clk", "xo";

		qcom,ctrl-supply-entries {
			#address-cells = <1>;
			#size-cells = <0>;

			qcom,ctrl-supply-entry@0 {
				reg = <0>;
				qcom,supply-name = "vdda-1p2";
				qcom,supply-min-voltage = <1200000>;
				qcom,supply-max-voltage = <1200000>;
				qcom,supply-enable-load = <30100>;
				qcom,supply-disable-load = <0>;
			};
		};

		qcom,core-supply-entries {
			#address-cells = <1>;
			#size-cells = <0>;
			qcom,core-supply-entry@0 {
				reg = <0>;
				qcom,supply-name = "refgen";
				qcom,supply-min-voltage = <0>;
				qcom,supply-max-voltage = <0>;
				qcom,supply-enable-load = <0>;
				qcom,supply-disable-load = <0>;
			};
		};
	};

	mdss_dsi_phy0: qcom,mdss_dsi_phy0@ae94400 {
		compatible = "qcom,dsi-phy-v4.2";
		label = "dsi-phy-0";
		cell-index = <0>;
		#clock-cells = <1>;

		reg = <0xae94400 0xa00>,
				<0xae94900 0x400>,
				<0xae94200 0xa0>;
		reg-names = "dsi_phy", "pll_base", "dyn_refresh_base";
		pll-label = "dsi_pll_5nm";

		qcom,platform-strength-ctrl = [55 03
				55 03
				55 03
				55 03
				55 00];
		qcom,platform-lane-config = [00 00 0a 0a
				00 00 0a 0a
				00 00 0a 0a
				00 00 0a 0a
				00 00 8a 8a];
		qcom,platform-regulator-settings = [1d 1d 1d 1d 1d];

		qcom,phy-supply-entries {
			#address-cells = <1>;
			#size-cells = <0>;
			qcom,phy-supply-entry@0 {
				reg = <0>;
				qcom,supply-name = "vdda-0p9";
				qcom,supply-min-voltage = <912000>;
				qcom,supply-max-voltage = <912000>;
				qcom,supply-enable-load = <115000>;
				qcom,supply-disable-load = <0>;
			};
		};
	};

	mdss_dsi_phy1: qcom,mdss_dsi_phy0@ae96400 {
		compatible = "qcom,dsi-phy-v4.2";
		label = "dsi-phy-1";
		cell-index = <1>;
		#clock-cells = <1>;
		reg = <0xae96400 0xa00>,
				<0xae96900 0x400>,
				<0xae96200 0xa0>;
		reg-names = "dsi_phy", "pll_base", "dyn_refresh_base";
		pll-label = "dsi_pll_5nm";

		qcom,platform-strength-ctrl = [55 03
				55 03
				55 03
				55 03
				55 00];
		qcom,platform-regulator-settings = [1d 1d 1d 1d 1d];
		qcom,platform-lane-config = [00 00 0a 0a
				00 00 0a 0a
				00 00 0a 0a
				00 00 0a 0a
				00 00 8a 8a];

		qcom,phy-supply-entries {
			#address-cells = <1>;
			#size-cells = <0>;
			qcom,phy-supply-entry@0 {
				reg = <0>;
				qcom,supply-name = "vdda-0p9";
				qcom,supply-min-voltage = <912000>;
				qcom,supply-max-voltage = <912000>;
				qcom,supply-enable-load = <115000>;
				qcom,supply-disable-load = <0>;
			};
		};
	};

	sde_edp0_pll: qcom,dp_pll@af54000 {
		compatible = "qcom,edp-pll-5nm";
		label = "mdss_0_edp0";
		#clock-cells = <1>;
	};

	qcom_msmhdcp0: qcom,msm_hdcp@0 {
		compatible = "qcom,msm-hdcp";
		cell-index = <0>;
		dpu-index = <0>;
		max_hdcp_key_verify_retries = <40>;
	};

	qcom_msmhdcp1: qcom,msm_hdcp@1 {
		compatible = "qcom,msm-hdcp";
		cell-index = <1>;
		dpu-index = <0>;
		max_hdcp_key_verify_retries = <40>;
		qcom,msm-hdcp-master = <&qcom_msmhdcp0>;
	};

	qcom_msmhdcp2: qcom,msm_hdcp@2 {
		compatible = "qcom,msm-hdcp";
		cell-index = <0>;
		dpu-index = <1>;
		max_hdcp_key_verify_retries = <40>;
		qcom,msm-hdcp-master = <&qcom_msmhdcp0>;
	};

	qcom_msmhdcp3: qcom,msm_hdcp@3 {
		compatible = "qcom,msm-hdcp";
		cell-index = <1>;
		dpu-index = <1>;
		max_hdcp_key_verify_retries = <40>;
		qcom,msm-hdcp-master = <&qcom_msmhdcp0>;
	};

	sde_dp_mst_sim0: qcom,dp-mst-sim@0 {
		compatible = "qcom,dp-mst-sim";
	};

	sde_dp_mst_sim1: qcom,dp-mst-sim@1 {
		compatible = "qcom,dp-mst-sim";
	};

	sde_dp_mst_sim2: qcom,dp-mst-sim@2 {
		compatible = "qcom,dp-mst-sim";
	};

	sde_dp_mst_sim3: qcom,dp-mst-sim@3 {
		compatible = "qcom,dp-mst-sim";
	};

	sde_edp0: qcom,dp_display@af54000 {
		cell-index = <0>;
		qcom,intf-index = <0 1>;
		compatible = "qcom,dp-display";
		label = "drm_edp0";

		reg = <0xaf54000 0x104>,
				<0xaf54200 0x0c0>,
				<0xaf55000 0x770>,
				<0xaf56000 0x09c>,
				<0xaec2a00 0x200>,
				<0xaec2200 0xd0>,
				<0xaec2600 0xd0>,
				<0xaec6000 0x18>,
				<0xaf08000 0x1f4>,
				<0xaec2000 0x1c8>,
				<0xaee1000 0x030>,
				<0xaf57000 0x09c>,
				<0xaf09000 0x14>;
		reg-names = "dp_ahb", "dp_aux", "dp_link",
				"dp_p0", "dp_phy", "dp_ln_tx0", "dp_ln_tx1",
				"ahb2phy", "dp_mmss_cc", "dp_pll",
				"hdcp_physical", "dp_p1", "gdsc";

		interrupt-parent = <&mdss_mdp>;
		interrupts = <12 0>;

		clocks = <&dispcc0 DISP_CC_MDSS_DPTX0_AUX_CLK>,
				<&gcc GCC_EDP_REF_CLKREF_EN>,
				<&rpmhcc RPMH_CXO_CLK>,
				<&dispcc0 DISP_CC_MDSS_DPTX0_LINK_CLK>,
				<&dispcc0 DISP_CC_MDSS_DPTX0_LINK_CLK_SRC>,
				<&dispcc0 DISP_CC_MDSS_DPTX0_LINK_INTF_CLK>,
				<&sde_edp0_pll 0>,
				<&dispcc0 DISP_CC_MDSS_DPTX0_PIXEL0_CLK_SRC>,
				<&sde_edp0_pll 1>,
				<&dispcc0 DISP_CC_MDSS_DPTX0_PIXEL1_CLK_SRC>,
				<&dispcc0 DISP_CC_MDSS_DPTX0_PIXEL0_CLK>,
				<&dispcc0 DISP_CC_MDSS_DPTX0_PIXEL1_CLK>;
		clock-names = "core_aux_clk", "core_ref_clk", "rpmh_cxo_clk",
				"link_clk", "link_clk_src", "link_iface_clk", "link_parent",
				"pixel_clk_rcg", "pixel_parent", "pixel1_clk_rcg",
				"strm0_pixel_clk", "strm1_pixel_clk";

		qcom,dp-pll = <&sde_edp0_pll>;
		qcom,phy-version = <0x500>;
		qcom,phy-mode = "edp";
		qcom,aux-cfg0-settings = [24 00];
		qcom,aux-cfg1-settings = [28 13];
		qcom,aux-cfg2-settings = [2c a4];
		qcom,aux-cfg3-settings = [30 00];
		qcom,aux-cfg4-settings = [34 0a];
		qcom,aux-cfg5-settings = [38 26];
		qcom,aux-cfg6-settings = [3c 0a];
		qcom,aux-cfg7-settings = [40 03];
		qcom,aux-cfg8-settings = [44 b7];
		qcom,aux-cfg9-settings = [48 03];

		qcom,msm-hdcp = <&qcom_msmhdcp0>;

		qcom,pixel-base-off = <0x188 0x1A0>;

		qcom,max-pclk-frequency-khz = <675000>;

		qcom,widebus-enable;
		qcom,mst-enable;
		qcom,fec-feature-enable;
		qcom,qos-cpu-mask = <0xf>;
		qcom,qos-cpu-latency-us = <300>;
		qcom,dp-aux-bridge = <&sde_dp_mst_sim0>;

		qcom,ctrl-supply-entries {
			#address-cells = <1>;
			#size-cells = <0>;

			qcom,ctrl-supply-entry@0 {
				reg = <0>;
				qcom,supply-name = "vdda-1p2";
				qcom,supply-min-voltage = <1200000>;
				qcom,supply-max-voltage = <1200000>;
				qcom,supply-enable-load = <30100>;
				qcom,supply-disable-load = <0>;
			};
		};

		qcom,phy-supply-entries {
			#address-cells = <1>;
			#size-cells = <0>;

			qcom,phy-supply-entry@0 {
				reg = <0>;
				qcom,supply-name = "vdda-0p9";
				qcom,supply-min-voltage = <912000>;
				qcom,supply-max-voltage = <912000>;
				qcom,supply-enable-load = <115000>;
				qcom,supply-disable-load = <0>;
			};
		};

		qcom,pll-supply-entries {
			#address-cells = <1>;
			#size-cells = <0>;

			qcom,pll-supply-entry@0 {
				reg = <0>;
				qcom,supply-name = "vdd_mx";
				qcom,supply-min-voltage =
						<RPMH_REGULATOR_LEVEL_TURBO>;
				qcom,supply-max-voltage =
						<RPMH_REGULATOR_LEVEL_MAX>;
				qcom,supply-enable-load = <0>;
				qcom,supply-disable-load = <0>;
			};
		};
	};

	sde_edp1_pll: qcom,dp_pll@af5c000 {
		compatible = "qcom,edp-pll-5nm";
		label = "mdss_0_edp1";
		#clock-cells = <1>;
	};

	sde_edp1: qcom,dp_display@af5c000 {
		cell-index = <1>;
		qcom,intf-index = <2 6>;
		compatible = "qcom,dp-display";
		label = "drm_edp1";

		reg = <0xaf5c000 0x104>,
				<0xaf5c200 0x0c0>,
				<0xaf5d000 0x770>,
				<0xaf5e000 0x09c>,
				<0xaec5a00 0x200>,
				<0xaec5200 0xd0>,
				<0xaec5600 0xd0>,
				<0xaec6000 0x18>,
				<0xaf08000 0x1f4>,
				<0xaec5000 0x1c8>,
				<0xaee2000 0x030>,
				<0xaf5f000 0x09c>,
				<0xaf09000 0x14>;
		reg-names = "dp_ahb", "dp_aux", "dp_link",
				"dp_p0", "dp_phy", "dp_ln_tx0", "dp_ln_tx1",
				"ahb2phy", "dp_mmss_cc", "dp_pll",
				"hdcp_physical", "dp_p1", "gdsc";

		interrupt-parent = <&mdss_mdp>;
		interrupts = <13 0>;

		clocks = <&dispcc0 DISP_CC_MDSS_DPTX1_AUX_CLK>,
				<&gcc GCC_EDP_REF_CLKREF_EN>,
				<&rpmhcc RPMH_CXO_CLK>,
				<&dispcc0 DISP_CC_MDSS_DPTX1_LINK_CLK>,
				<&dispcc0 DISP_CC_MDSS_DPTX1_LINK_CLK_SRC>,
				<&dispcc0 DISP_CC_MDSS_DPTX1_LINK_INTF_CLK>,
				<&sde_edp1_pll 0>,
				<&dispcc0 DISP_CC_MDSS_DPTX1_PIXEL0_CLK_SRC>,
				<&sde_edp1_pll 1>,
				<&dispcc0 DISP_CC_MDSS_DPTX1_PIXEL1_CLK_SRC>,
				<&dispcc0 DISP_CC_MDSS_DPTX1_PIXEL0_CLK>,
				<&dispcc0 DISP_CC_MDSS_DPTX1_PIXEL1_CLK>;
		clock-names = "core_aux_clk", "core_ref_clk", "rpmh_cxo_clk",
				"link_clk", "link_clk_src", "link_iface_clk", "link_parent",
				"pixel_clk_rcg", "pixel_parent", "pixel1_clk_rcg",
				"strm0_pixel_clk", "strm1_pixel_clk";

		qcom,dp-pll = <&sde_edp1_pll>;
		qcom,phy-version = <0x500>;
		qcom,phy-mode = "edp";
		qcom,aux-cfg0-settings = [24 00];
		qcom,aux-cfg1-settings = [28 13];
		qcom,aux-cfg2-settings = [2c a4];
		qcom,aux-cfg3-settings = [30 00];
		qcom,aux-cfg4-settings = [34 0a];
		qcom,aux-cfg5-settings = [38 26];
		qcom,aux-cfg6-settings = [3c 0a];
		qcom,aux-cfg7-settings = [40 03];
		qcom,aux-cfg8-settings = [44 b7];
		qcom,aux-cfg9-settings = [48 03];

		qcom,msm-hdcp = <&qcom_msmhdcp1>;

		qcom,pixel-base-off = <0x1D0 0x1E8>;

		qcom,max-pclk-frequency-khz = <675000>;

		qcom,widebus-enable;
		qcom,mst-enable;
		qcom,fec-feature-enable;
		qcom,qos-cpu-mask = <0xf>;
		qcom,qos-cpu-latency-us = <300>;
		qcom,dp-aux-bridge = <&sde_dp_mst_sim1>;

		qcom,ctrl-supply-entries {
			#address-cells = <1>;
			#size-cells = <0>;

			qcom,ctrl-supply-entry@0 {
				reg = <0>;
				qcom,supply-name = "vdda-1p2";
				qcom,supply-min-voltage = <1200000>;
				qcom,supply-max-voltage = <1200000>;
				qcom,supply-enable-load = <30100>;
				qcom,supply-disable-load = <0>;
			};
		};

		qcom,phy-supply-entries {
			#address-cells = <1>;
			#size-cells = <0>;

			qcom,phy-supply-entry@0 {
				reg = <0>;
				qcom,supply-name = "vdda-0p9";
				qcom,supply-min-voltage = <912000>;
				qcom,supply-max-voltage = <912000>;
				qcom,supply-enable-load = <115000>;
				qcom,supply-disable-load = <0>;
			};
		};

		qcom,pll-supply-entries {
			#address-cells = <1>;
			#size-cells = <0>;

			qcom,pll-supply-entry@0 {
				reg = <0>;
				qcom,supply-name = "vdd_mx";
				qcom,supply-min-voltage =
						<RPMH_REGULATOR_LEVEL_TURBO>;
				qcom,supply-max-voltage =
						<RPMH_REGULATOR_LEVEL_MAX>;
				qcom,supply-enable-load = <0>;
				qcom,supply-disable-load = <0>;
			};
		};
	};

	sde_edp2_pll: qcom,dp_pll@22154000 {
		compatible = "qcom,edp-pll-5nm";
		label = "mdss_1_edp2";
		#clock-cells = <1>;
	};

	sde_edp2: qcom,dp_display@22154000 {
		cell-index = <2>;
		qcom,intf-index = <0 1>;
		compatible = "qcom,dp-display";
		label = "drm_edp2";

		reg = <0x22154000 0x104>,
				<0x22154200 0x0c0>,
				<0x22155000 0x770>,
				<0x22156000 0x09c>,
				<0x220c2a00 0x200>,
				<0x220c2200 0xd0>,
				<0x220c2600 0xd0>,
				<0x220c6000 0x18>,
				<0x22108000 0x1f4>,
				<0x220c2000 0x1c8>,
				<0x220e1000 0x030>,
				<0x22157000 0x09c>,
				<0x22109000 0x14>;
		reg-names = "dp_ahb", "dp_aux", "dp_link",
				"dp_p0", "dp_phy", "dp_ln_tx0", "dp_ln_tx1",
				"ahb2phy", "dp_mmss_cc", "dp_pll",
				"hdcp_physical", "dp_p1", "gdsc";

		interrupt-parent = <&mdss_mdp1>;
		interrupts = <12 0>;

		clocks = <&dispcc1 DISP_CC_MDSS_DPTX0_AUX_CLK>,
				<&gcc GCC_EDP_REF_CLKREF_EN>,
				<&rpmhcc RPMH_CXO_CLK>,
				<&dispcc1 DISP_CC_MDSS_DPTX0_LINK_CLK>,
				<&dispcc1 DISP_CC_MDSS_DPTX0_LINK_CLK_SRC>,
				<&dispcc1 DISP_CC_MDSS_DPTX0_LINK_INTF_CLK>,
				<&sde_edp2_pll 0>,
				<&dispcc1 DISP_CC_MDSS_DPTX0_PIXEL0_CLK_SRC>,
				<&sde_edp2_pll 1>,
				<&dispcc1 DISP_CC_MDSS_DPTX0_PIXEL1_CLK_SRC>,
				<&dispcc1 DISP_CC_MDSS_DPTX0_PIXEL0_CLK>,
				<&dispcc1 DISP_CC_MDSS_DPTX0_PIXEL1_CLK>;
		clock-names = "core_aux_clk", "core_ref_clk", "rpmh_cxo_clk",
				"link_clk", "link_clk_src", "link_iface_clk", "link_parent",
				"pixel_clk_rcg", "pixel_parent", "pixel1_clk_rcg",
				"strm0_pixel_clk", "strm1_pixel_clk";

		qcom,dp-pll = <&sde_edp2_pll>;
		qcom,phy-version = <0x500>;
		qcom,phy-mode = "edp";
		qcom,aux-cfg0-settings = [24 00];
		qcom,aux-cfg1-settings = [28 13];
		qcom,aux-cfg2-settings = [2c a4];
		qcom,aux-cfg3-settings = [30 00];
		qcom,aux-cfg4-settings = [34 0a];
		qcom,aux-cfg5-settings = [38 26];
		qcom,aux-cfg6-settings = [3c 0a];
		qcom,aux-cfg7-settings = [40 03];
		qcom,aux-cfg8-settings = [44 b7];
		qcom,aux-cfg9-settings = [48 03];

		qcom,msm-hdcp = <&qcom_msmhdcp2>;

		qcom,pixel-base-off = <0x188 0x1A0>;

		qcom,max-pclk-frequency-khz = <675000>;

		qcom,widebus-enable;
		qcom,mst-enable;
		qcom,fec-feature-enable;
		qcom,qos-cpu-mask = <0xf>;
		qcom,qos-cpu-latency-us = <300>;
		qcom,dp-aux-bridge = <&sde_dp_mst_sim2>;

		qcom,ctrl-supply-entries {
			#address-cells = <1>;
			#size-cells = <0>;

			qcom,ctrl-supply-entry@0 {
				reg = <0>;
				qcom,supply-name = "vdda-1p2";
				qcom,supply-min-voltage = <1200000>;
				qcom,supply-max-voltage = <1200000>;
				qcom,supply-enable-load = <30100>;
				qcom,supply-disable-load = <0>;
			};
		};

		qcom,phy-supply-entries {
			#address-cells = <1>;
			#size-cells = <0>;

			qcom,phy-supply-entry@0 {
				reg = <0>;
				qcom,supply-name = "vdda-0p9";
				qcom,supply-min-voltage = <912000>;
				qcom,supply-max-voltage = <912000>;
				qcom,supply-enable-load = <115000>;
				qcom,supply-disable-load = <0>;
			};
		};

		qcom,pll-supply-entries {
			#address-cells = <1>;
			#size-cells = <0>;

			qcom,pll-supply-entry@0 {
				reg = <0>;
				qcom,supply-name = "vdd_mx";
				qcom,supply-min-voltage =
						<RPMH_REGULATOR_LEVEL_TURBO>;
				qcom,supply-max-voltage =
						<RPMH_REGULATOR_LEVEL_MAX>;
				qcom,supply-enable-load = <0>;
				qcom,supply-disable-load = <0>;
			};
		};
	};

	sde_edp3_pll: qcom,dp_pll@220a0000 {
		compatible = "qcom,edp-pll-5nm";
		label = "mdss_1_edp3";
		#clock-cells = <1>;
	};

	sde_edp3: qcom,dp_display@220a0000 {
		cell-index = <3>;
		qcom,intf-index = <2 6>;
		compatible = "qcom,dp-display";
		label = "drm_edp3";

		reg = <0x2215c000 0x104>,
				<0x2215c200 0x0c0>,
				<0x2215d000 0x770>,
				<0x2215e000 0x09c>,
				<0x220c5a00 0x200>,
				<0x220c5200 0xd0>,
				<0x220c5600 0xd0>,
				<0x220c6000 0x18>,
				<0x22108000 0x1f4>,
				<0x220c5000 0x1c8>,
				<0x220e2000 0x030>,
				<0x2215f000 0x09c>,
				<0x22109000 0x14>;
		reg-names = "dp_ahb", "dp_aux", "dp_link",
				"dp_p0", "dp_phy", "dp_ln_tx0", "dp_ln_tx1",
				"ahb2phy", "dp_mmss_cc", "dp_pll",
				"hdcp_physical", "dp_p1", "gdsc";

		interrupt-parent = <&mdss_mdp1>;
		interrupts = <13 0>;

		clocks = <&dispcc1 DISP_CC_MDSS_DPTX1_AUX_CLK>,
				<&gcc GCC_EDP_REF_CLKREF_EN>,
				<&rpmhcc RPMH_CXO_CLK>,
				<&dispcc1 DISP_CC_MDSS_DPTX1_LINK_CLK>,
				<&dispcc1 DISP_CC_MDSS_DPTX1_LINK_CLK_SRC>,
				<&dispcc1 DISP_CC_MDSS_DPTX1_LINK_INTF_CLK>,
				<&sde_edp3_pll 0>,
				<&dispcc1 DISP_CC_MDSS_DPTX1_PIXEL0_CLK_SRC>,
				<&sde_edp3_pll 1>,
				<&dispcc1 DISP_CC_MDSS_DPTX1_PIXEL1_CLK_SRC>,
				<&dispcc1 DISP_CC_MDSS_DPTX1_PIXEL0_CLK>,
				<&dispcc1 DISP_CC_MDSS_DPTX1_PIXEL1_CLK>;
		clock-names = "core_aux_clk", "core_ref_clk", "rpmh_cxo_clk",
				"link_clk", "link_clk_src", "link_iface_clk", "link_parent",
				"pixel_clk_rcg", "pixel_parent", "pixel1_clk_rcg",
				"strm0_pixel_clk", "strm1_pixel_clk";

		qcom,dp-pll = <&sde_edp3_pll>;
		qcom,phy-version = <0x500>;
		qcom,phy-mode = "edp";
		qcom,aux-cfg0-settings = [24 00];
		qcom,aux-cfg1-settings = [28 13];
		qcom,aux-cfg2-settings = [2c a4];
		qcom,aux-cfg3-settings = [30 00];
		qcom,aux-cfg4-settings = [34 0a];
		qcom,aux-cfg5-settings = [38 26];
		qcom,aux-cfg6-settings = [3c 0a];
		qcom,aux-cfg7-settings = [40 03];
		qcom,aux-cfg8-settings = [44 b7];
		qcom,aux-cfg9-settings = [48 03];

		qcom,msm-hdcp = <&qcom_msmhdcp3>;

		qcom,pixel-base-off = <0x1D0 0x1E8>;

		qcom,max-pclk-frequency-khz = <675000>;

		qcom,widebus-enable;
		qcom,mst-enable;
		qcom,fec-feature-enable;
		qcom,qos-cpu-mask = <0xf>;
		qcom,qos-cpu-latency-us = <300>;
		qcom,dp-aux-bridge = <&sde_dp_mst_sim3>;

		qcom,ctrl-supply-entries {
			#address-cells = <1>;
			#size-cells = <0>;

			qcom,ctrl-supply-entry@0 {
				reg = <0>;
				qcom,supply-name = "vdda-1p2";
				qcom,supply-min-voltage = <1200000>;
				qcom,supply-max-voltage = <1200000>;
				qcom,supply-enable-load = <30100>;
				qcom,supply-disable-load = <0>;
			};
		};

		qcom,phy-supply-entries {
			#address-cells = <1>;
			#size-cells = <0>;

			qcom,phy-supply-entry@0 {
				reg = <0>;
				qcom,supply-name = "vdda-0p9";
				qcom,supply-min-voltage = <912000>;
				qcom,supply-max-voltage = <912000>;
				qcom,supply-enable-load = <115000>;
				qcom,supply-disable-load = <0>;
			};
		};

		qcom,pll-supply-entries {
			#address-cells = <1>;
			#size-cells = <0>;

			qcom,pll-supply-entry@0 {
				reg = <0>;
				qcom,supply-name = "vdd_mx";
				qcom,supply-min-voltage =
						<RPMH_REGULATOR_LEVEL_TURBO>;
				qcom,supply-max-voltage =
						<RPMH_REGULATOR_LEVEL_MAX>;
				qcom,supply-enable-load = <0>;
				qcom,supply-disable-load = <0>;
			};
		};
	};
};

&dispcc0 {
	clocks = <&rpmhcc RPMH_CXO_CLK>, <&rpmhcc RPMH_CXO_CLK_A>,
			<&sleep_clk>, <&gcc GCC_DISP_AHB_CLK>,
			<&mdss_dsi_phy0 0>, <&mdss_dsi_phy0 1>,
			<&mdss_dsi_phy1 2>, <&mdss_dsi_phy1 3>,
			<&sde_edp0_pll 0>, <&sde_edp0_pll 1>,
			<&sde_edp1_pll 0>, <&sde_edp1_pll 1>;
	clock-names = "bi_tcxo", "bi_tcxo_ao", "sleep_clk", "iface",
			"dsi0_phy_pll_out_byteclk", "dsi0_phy_pll_out_dsiclk",
			"dsi1_phy_pll_out_byteclk", "dsi1_phy_pll_out_dsiclk",
			"dp0_phy_pll_link_clk", "dp0_phy_pll_vco_div_clk",
			"dp1_phy_pll_link_clk", "dp1_phy_pll_vco_div_clk";
};

&dispcc1 {
	clocks = <&rpmhcc RPMH_CXO_CLK>, <&rpmhcc RPMH_CXO_CLK_A>,
			<&sleep_clk>, <&gcc GCC_DISP1_AHB_CLK>,
			<&sde_edp2_pll 0>, <&sde_edp2_pll 1>,
			<&sde_edp3_pll 0>, <&sde_edp3_pll 1>;
	clock-names = "bi_tcxo", "bi_tcxo_ao", "sleep_clk", "iface",
			"dp0_phy_pll_link_clk", "dp0_phy_pll_vco_div_clk",
			"dp1_phy_pll_link_clk", "dp1_phy_pll_vco_div_clk";
};
